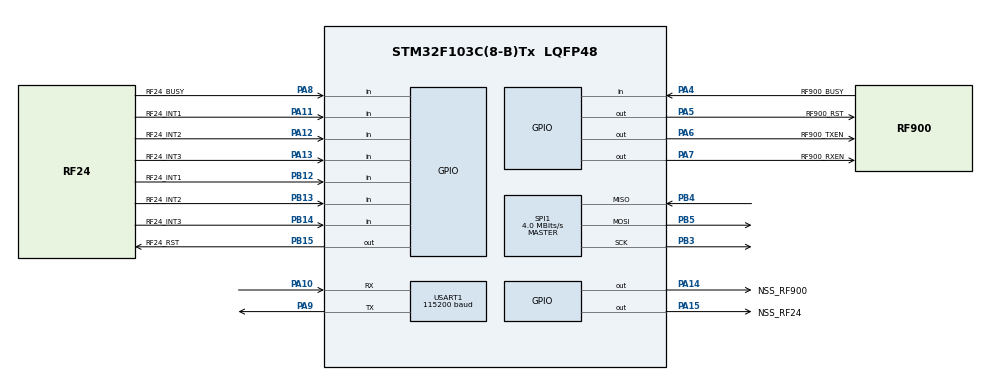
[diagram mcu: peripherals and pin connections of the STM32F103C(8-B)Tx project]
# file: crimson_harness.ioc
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Dma.Request0=USART1_RX
Dma.Request1=USART1_TX
Dma.USART1_RX.0.Direction=DMA_PERIPH_TO_MEMORY
Dma.USART1_RX.0.Instance=DMA1_Channel5
Dma.USART1_RX.0.MemDataAlignment=DMA_MDATAALIGN_BYTE
Dma.USART1_RX.0.MemInc=DMA_MINC_ENABLE
Dma.USART1_RX.0.Mode=DMA_CIRCULAR
Dma.USART1_RX.0.PeriphDataAlignment=DMA_PDATAALIGN_BYTE
Dma.USART1_RX.0.PeriphInc=DMA_PINC_DISABLE
Dma.USART1_RX.0.Priority=DMA_PRIORITY_HIGH
Dma.USART1_TX.1.Direction=DMA_MEMORY_TO_PERIPH
Dma.USART1_TX.1.Instance=DMA1_Channel4
Dma.USART1_TX.1.MemDataAlignment=DMA_MDATAALIGN_BYTE
Dma.USART1_TX.1.MemInc=DMA_MINC_ENABLE
Dma.USART1_TX.1.Mode=DMA_NORMAL
Dma.USART1_TX.1.PeriphDataAlignment=DMA_PDATAALIGN_BYTE
Dma.USART1_TX.1.PeriphInc=DMA_PINC_DISABLE
Dma.USART1_TX.1.Priority=DMA_PRIORITY_HIGH
IWDG.Prescaler=IWDG_PRESCALER_16
IWDG.Reload=2500
Mcu.Family=STM32F1
Mcu.Name=STM32F103C(8-B)Tx
Mcu.Package=LQFP48
NVIC.DMA1_Channel4_IRQn=true\:0\:0\:false\:false\:true\:false\:true\:true
NVIC.DMA1_Channel5_IRQn=true\:0\:0\:false\:false\:true\:false\:true\:true
NVIC.PriorityGroup=NVIC_PRIORITYGROUP_4
NVIC.USART1_IRQn=true\:0\:0\:false\:false\:true\:true\:true\:true
PA10.Mode=Asynchronous
PA10.Signal=USART1_RX
PA11.GPIO_Label=RF24_INT1
PA11.Signal=GPIO_Input
PA12.GPIO_Label=RF24_INT2
PA12.Signal=GPIO_Input
PA13.GPIO_Label=RF24_INT3
PA13.Signal=GPIO_Input
PA14.GPIO_Label=NSS_RF900
PA14.Signal=GPIO_Output
PA15.GPIO_Label=NSS_RF24
PA15.Signal=GPIO_Output
PA4.GPIO_Label=RF900_BUSY
PA4.Signal=GPIO_Input
PA5.GPIO_Label=RF900_RST
PA5.Signal=GPIO_Output
PA6.GPIO_Label=RF900_TXEN
PA6.Signal=GPIO_Output
PA7.GPIO_Label=RF900_RXEN
PA7.Signal=GPIO_Output
PA8.GPIO_Label=RF24_BUSY
PA8.Signal=GPIO_Input
PA9.Mode=Asynchronous
PA9.Signal=USART1_TX
PB12.GPIO_Label=RF24_INT1
PB12.Signal=GPIO_Input
PB13.GPIO_Label=RF24_INT2
PB13.Signal=GPIO_Input
PB14.GPIO_Label=RF24_INT3
PB14.Signal=GPIO_Input
PB15.GPIO_Label=RF24_RST
PB15.Signal=GPIO_Output
PB3.Mode=Full_Duplex_Master
PB3.Signal=SPI1_SCK
PB4.Mode=Full_Duplex_Master
PB4.Signal=SPI1_MISO
PB5.Mode=Full_Duplex_Master
PB5.Signal=SPI1_MOSI
ProjectManager.HeapSize=0x200
ProjectManager.StackSize=0x400
ProjectManager.TargetToolchain=CMake
RCC.APB1Freq_Value=8000000
RCC.APB2Freq_Value=8000000
SPI1.CalculateBaudRate=4.0 MBits/s
SPI1.Direction=SPI_DIRECTION_2LINES
SPI1.Mode=SPI_MODE_MASTER
SPI1.VirtualType=VM_MASTER
USART1.BaudRate=115200
USART1.Parity=PARITY_NONE
USART1.VirtualMode=VM_ASYNC
VP_IWDG_VS_IWDG.Mode=IWDG_Activate
VP_SYS_VS_ND.Mode=No_Debug
board=custom

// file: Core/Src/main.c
/* USER CODE BEGIN Header */
/**
  ******************************************************************************
  * @file           : main.c
  * @brief          : Main program body
  ******************************************************************************
  * @attention
  *
  * Copyright (c) 2026 STMicroelectronics.
  * All rights reserved.
  *
  * This software is licensed under terms that can be found in the LICENSE file
  * in the root directory of this software component.
  * If no LICENSE file comes with this software, it is provided AS-IS.
  *
  ******************************************************************************
  */
/* USER CODE END Header */
#include "main.h"

/* USER CODE BEGIN Includes */
#include "radio_harness.h"
#include "app_error.h"
/* USER CODE END Includes */

IWDG_HandleTypeDef hiwdg;

SPI_HandleTypeDef hspi1;

UART_HandleTypeDef huart1;
DMA_HandleTypeDef hdma_usart1_rx;
DMA_HandleTypeDef hdma_usart1_tx;

void SystemClock_Config(void);
static void MX_GPIO_Init(void);
static void MX_DMA_Init(void);
static void MX_SPI1_Init(void);
static void MX_USART1_UART_Init(void);
static void MX_IWDG_Init(void);

int main(void)
{

  /* MCU Configuration--------------------------------------------------------*/

  /* Reset of all peripherals, Initializes the Flash interface and the Systick. */
  HAL_Init();

  /* Configure the system clock */
  SystemClock_Config();

  /* Initialize all configured peripherals */
  MX_GPIO_Init();
  MX_DMA_Init();
  MX_SPI1_Init();
  MX_USART1_UART_Init();
  MX_IWDG_Init();
  /* USER CODE BEGIN 2 */
  radio_harness_init();
  /* USER CODE END 2 */

  /* Infinite loop */
  /* USER CODE BEGIN WHILE */
  while (1)
  {
    radio_harness_poll();
    /* USER CODE END WHILE */

    /* USER CODE BEGIN 3 */
    /* Every path through the poll loop is bounded (busy-wait, SPI and TX
       deadlines), so one refresh per pass proves liveness. 1 s timeout vs.
       a worst-case pass of ~400 ms with a radio in re-init. */
    HAL_IWDG_Refresh(&hiwdg);
  }
  /* USER CODE END 3 */
}

void SystemClock_Config(void)
{
  RCC_OscInitTypeDef RCC_OscInitStruct = {0};
  RCC_ClkInitTypeDef RCC_ClkInitStruct = {0};

  /** Initializes the RCC Oscillators according to the specified parameters
  * in the RCC_OscInitTypeDef structure.
  */
  RCC_OscInitStruct.OscillatorType = RCC_OSCILLATORTYPE_HSI|RCC_OSCILLATORTYPE_LSI;
  RCC_OscInitStruct.HSIState = RCC_HSI_ON;
  RCC_OscInitStruct.HSICalibrationValue = RCC_HSICALIBRATION_DEFAULT;
  RCC_OscInitStruct.LSIState = RCC_LSI_ON;
  RCC_OscInitStruct.PLL.PLLState = RCC_PLL_NONE;
  if (HAL_RCC_OscConfig(&RCC_OscInitStruct) != HAL_OK)
  {
    Error_Handler();
  }

  /** Initializes the CPU, AHB and APB buses clocks
  */
  RCC_ClkInitStruct.ClockType = RCC_CLOCKTYPE_HCLK|RCC_CLOCKTYPE_SYSCLK
                              |RCC_CLOCKTYPE_PCLK1|RCC_CLOCKTYPE_PCLK2;
  RCC_ClkInitStruct.SYSCLKSource = RCC_SYSCLKSOURCE_HSI;
  RCC_ClkInitStruct.AHBCLKDivider = RCC_SYSCLK_DIV1;
  RCC_ClkInitStruct.APB1CLKDivider = RCC_HCLK_DIV1;
  RCC_ClkInitStruct.APB2CLKDivider = RCC_HCLK_DIV1;

  if (HAL_RCC_ClockConfig(&RCC_ClkInitStruct, FLASH_LATENCY_0) != HAL_OK)
  {
    Error_Handler();
  }
}

static void MX_IWDG_Init(void)
{

  hiwdg.Instance = IWDG;
  hiwdg.Init.Prescaler = IWDG_PRESCALER_16;
  hiwdg.Init.Reload = 2500;
  if (HAL_IWDG_Init(&hiwdg) != HAL_OK)
  {
    Error_Handler();
  }

}

static void MX_SPI1_Init(void)
{

  /* SPI1 parameter configuration*/
  hspi1.Instance = SPI1;
  hspi1.Init.Mode = SPI_MODE_MASTER;
  hspi1.Init.Direction = SPI_DIRECTION_2LINES;
  hspi1.Init.DataSize = SPI_DATASIZE_8BIT;
  hspi1.Init.CLKPolarity = SPI_POLARITY_LOW;
  hspi1.Init.CLKPhase = SPI_PHASE_1EDGE;
  hspi1.Init.NSS = SPI_NSS_SOFT;
  hspi1.Init.BaudRatePrescaler = SPI_BAUDRATEPRESCALER_2;
  hspi1.Init.FirstBit = SPI_FIRSTBIT_MSB;
  hspi1.Init.TIMode = SPI_TIMODE_DISABLE;
  hspi1.Init.CRCCalculation = SPI_CRCCALCULATION_DISABLE;
  hspi1.Init.CRCPolynomial = 10;
  if (HAL_SPI_Init(&hspi1) != HAL_OK)
  {
    Error_Handler();
  }

}

static void MX_USART1_UART_Init(void)
{

  huart1.Instance = USART1;
  huart1.Init.BaudRate = 115200;
  huart1.Init.WordLength = UART_WORDLENGTH_8B;
  huart1.Init.StopBits = UART_STOPBITS_1;
  huart1.Init.Parity = UART_PARITY_NONE;
  huart1.Init.Mode = UART_MODE_TX_RX;
  huart1.Init.HwFlowCtl = UART_HWCONTROL_NONE;
  huart1.Init.OverSampling = UART_OVERSAMPLING_16;
  if (HAL_UART_Init(&huart1) != HAL_OK)
  {
    Error_Handler();
  }

}

static void MX_DMA_Init(void)
{

  /* DMA controller clock enable */
  __HAL_RCC_DMA1_CLK_ENABLE();

  /* DMA interrupt init */
  /* DMA1_Channel4_IRQn interrupt configuration */
  HAL_NVIC_SetPriority(DMA1_Channel4_IRQn, 0, 0);
  HAL_NVIC_EnableIRQ(DMA1_Channel4_IRQn);
  /* DMA1_Channel5_IRQn interrupt configuration */
  HAL_NVIC_SetPriority(DMA1_Channel5_IRQn, 0, 0);
  HAL_NVIC_EnableIRQ(DMA1_Channel5_IRQn);

}

static void MX_GPIO_Init(void)
{
  GPIO_InitTypeDef GPIO_InitStruct = {0};

  /* GPIO Ports Clock Enable */
  __HAL_RCC_GPIOA_CLK_ENABLE();
  __HAL_RCC_GPIOB_CLK_ENABLE();

  /*Configure GPIO pin Output Level */
  HAL_GPIO_WritePin(GPIOA, RF900_RST_Pin|RF900_TXEN_Pin|RF900_RXEN_Pin|NSS_RF900_Pin
                          |NSS_RF24_Pin, GPIO_PIN_RESET);

  /*Configure GPIO pin Output Level */
  HAL_GPIO_WritePin(RF24_RST_GPIO_Port, RF24_RST_Pin, GPIO_PIN_RESET);

  /*Configure GPIO pins : RF900_BUSY_Pin RF24_BUSY_Pin RF24_INT1A11_Pin RF24_INT2A12_Pin
                           RF24_INT3A13_Pin */
  GPIO_InitStruct.Pin = RF900_BUSY_Pin|RF24_BUSY_Pin|RF24_INT1A11_Pin|RF24_INT2A12_Pin
                          |RF24_INT3A13_Pin;
  GPIO_InitStruct.Mode = GPIO_MODE_INPUT;
  GPIO_InitStruct.Pull = GPIO_NOPULL;
  HAL_GPIO_Init(GPIOA, &GPIO_InitStruct);

  /*Configure GPIO pins : RF900_RST_Pin RF900_TXEN_Pin RF900_RXEN_Pin NSS_RF900_Pin
                           NSS_RF24_Pin */
  GPIO_InitStruct.Pin = RF900_RST_Pin|RF900_TXEN_Pin|RF900_RXEN_Pin|NSS_RF900_Pin
                          |NSS_RF24_Pin;
  GPIO_InitStruct.Mode = GPIO_MODE_OUTPUT_PP;
  GPIO_InitStruct.Pull = GPIO_NOPULL;
  GPIO_InitStruct.Speed = GPIO_SPEED_FREQ_LOW;
  HAL_GPIO_Init(GPIOA, &GPIO_InitStruct);

  /*Configure GPIO pins : RF24_INT1_Pin RF24_INT2_Pin RF24_INT3_Pin */
  GPIO_InitStruct.Pin = RF24_INT1_Pin|RF24_INT2_Pin|RF24_INT3_Pin;
  GPIO_InitStruct.Mode = GPIO_MODE_INPUT;
  GPIO_InitStruct.Pull = GPIO_NOPULL;
  HAL_GPIO_Init(GPIOB, &GPIO_InitStruct);

  /*Configure GPIO pin : RF24_RST_Pin */
  GPIO_InitStruct.Pin = RF24_RST_Pin;
  GPIO_InitStruct.Mode = GPIO_MODE_OUTPUT_PP;
  GPIO_InitStruct.Pull = GPIO_NOPULL;
  GPIO_InitStruct.Speed = GPIO_SPEED_FREQ_LOW;
  HAL_GPIO_Init(RF24_RST_GPIO_Port, &GPIO_InitStruct);

}

void Error_Handler(void)
{
  /* USER CODE BEGIN Error_Handler_Debug */
  /* Record the failure in a backup register and reset; a controlled reboot
     recovers the radio links, an infinite loop with IRQs off never does. */
  app_error_fatal(APP_ERR_HAL);
  /* USER CODE END Error_Handler_Debug */
}
